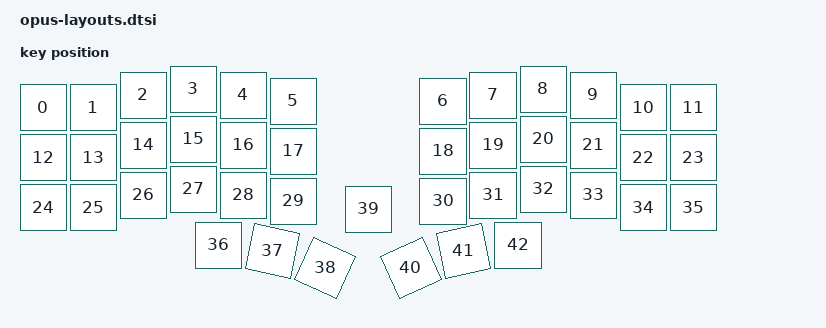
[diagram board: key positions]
#include <physical_layouts.dtsi>

// generated using
// https://zmk-physical-layout-converter.streamlit.app/?layout=H4sIAAAAAAACA4WRwU7DMBBE7_2KVc5tlJl12oQrn4E4cC9UClQiivLvmGAlprjMyfb6adbeN-3MqvPLeLl-vFcPNsVjLBzt8XK-vr6tlRWKladUMZus-oyFpm72Vo3Lzk82728BKIAZABYAz4CmcB9UQJsBDAWgU0CvWqARjwRkBOUoXRHbK6BsQNmAsgFhA8oGlA0oG5A2oGxA2oC0AWWDygaVDSobFDaobFDZoLJBaYPKBqUNSht3CK_bBHi5SfgFxO2wdR42YBiX7Z1phm7NcE8ZDFtGIlKIeyHkuL6DdWngp7rl3yaHvEv3g_zXpSv99pB_t5ff7W9Gmu6fl_X7NO_mL4aqlDllBgAA

/ {
    physical_layout0: physical_layout_0 {
        compatible = "zmk,physical-layout";
        display-name = "6 Column";

        kscan = <&kscan0>;
        transform = <&default_transform>;

        keys  //                     w   h    x    y     rot    rx    ry
            = <&key_physical_attrs 100 100    0   37       0     0     0>
            , <&key_physical_attrs 100 100  100   37       0     0     0>
            , <&key_physical_attrs 100 100  200   12       0     0     0>
            , <&key_physical_attrs 100 100  300    0       0     0     0>
            , <&key_physical_attrs 100 100  400   12       0     0     0>
            , <&key_physical_attrs 100 100  500   24       0     0     0>
            , <&key_physical_attrs 100 100  800   24       0     0     0>
            , <&key_physical_attrs 100 100  900   12       0     0     0>
            , <&key_physical_attrs 100 100 1000    0       0     0     0>
            , <&key_physical_attrs 100 100 1100   12       0     0     0>
            , <&key_physical_attrs 100 100 1200   37       0     0     0>
            , <&key_physical_attrs 100 100 1300   37       0     0     0>
            , <&key_physical_attrs 100 100    0  137       0     0     0>
            , <&key_physical_attrs 100 100  100  137       0     0     0>
            , <&key_physical_attrs 100 100  200  112       0     0     0>
            , <&key_physical_attrs 100 100  300  100       0     0     0>
            , <&key_physical_attrs 100 100  400  112       0     0     0>
            , <&key_physical_attrs 100 100  500  124       0     0     0>
            , <&key_physical_attrs 100 100  800  124       0     0     0>
            , <&key_physical_attrs 100 100  900  112       0     0     0>
            , <&key_physical_attrs 100 100 1000  100       0     0     0>
            , <&key_physical_attrs 100 100 1100  112       0     0     0>
            , <&key_physical_attrs 100 100 1200  137       0     0     0>
            , <&key_physical_attrs 100 100 1300  137       0     0     0>
            , <&key_physical_attrs 100 100    0  237       0     0     0>
            , <&key_physical_attrs 100 100  100  237       0     0     0>
            , <&key_physical_attrs 100 100  200  212       0     0     0>
            , <&key_physical_attrs 100 100  300  200       0     0     0>
            , <&key_physical_attrs 100 100  400  212       0     0     0>
            , <&key_physical_attrs 100 100  500  224       0     0     0>
            , <&key_physical_attrs 100 100  800  224       0     0     0>
            , <&key_physical_attrs 100 100  900  212       0     0     0>
            , <&key_physical_attrs 100 100 1000  200       0     0     0>
            , <&key_physical_attrs 100 100 1100  212       0     0     0>
            , <&key_physical_attrs 100 100 1200  237       0     0     0>
            , <&key_physical_attrs 100 100 1300  237       0     0     0>
            , <&key_physical_attrs 100 100  350  312       0     0     0>
            , <&key_physical_attrs 100 100  450  312    1200   450   412>
            , <&key_physical_attrs 100 100  548  333    2400   548   433>
            , <&key_physical_attrs 100 100  650  240       0     0     0>
            , <&key_physical_attrs 100 100  752  333 (-2400)   852   433>
            , <&key_physical_attrs 100 100  850  312 (-1200)   950   412>
            , <&key_physical_attrs 100 100  950  312       0     0     0>
            ;
    };
};
